# RA register map
Vendor: Renesas; Series: All Chips; File version: x.xx
Registers are 32-bit, read-write, reset 0x0 unless marked. A register's access mark holds for its fields unless they carry their own. Offsets are from the block's base; [hi:lo] are bit positions; {n}, {i} and the like mark numbered series; 'fields as' and 'values as' point back to an identical list.

## R_SDADC0
Base 0x4009C000
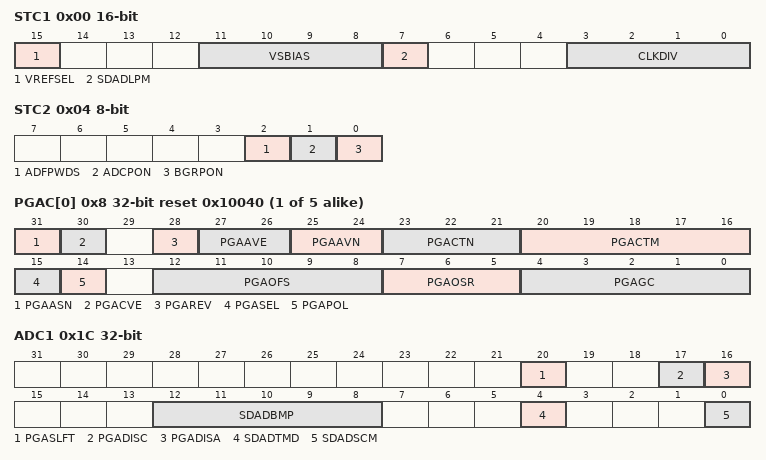
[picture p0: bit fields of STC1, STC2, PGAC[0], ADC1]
0x00 STC1 16-bit reset not defined — Startup Control Register 1
  [15] VREFSEL — VREF mode select
    0=Internal VREF Mode
  [11:8] VSBIAS — Reference voltage select
    0=0.8V; 1=1.0V; 2=1.2V; 3=1.4V; 4=1.6V; 5=1.8V; 6=2.0V; 7=2.2V; 15=2.4V(only available when VREFSEL=0)
  [7] SDADLPM — A/D conversion operation model select
    0=Normal A/D conversion mode, SDADC Reference Clock: 4 MHz, Oversampingly clock: 1MHz
  [3:0] CLKDIV — SDADC24 Reference Clock Division
    0=No Division; {v}=SDADCCLK/{v+1} (v=1..5); 6=SDADCCLK/8; 7=SDADCCLK/12; 8=SDADCCLK/16
0x04 STC2 8-bit — Startup Control Register 2
  [2] ADFPWDS — ADC reference supply part
    0=Power of ADREG controlled by BGRPON register; 1=Power of ADREG is off regardless of BGRPON setting
  [1] ADCPON — ADREG forced power-down
    0=Turn off power to VBIAS, PGA and sigma-delta A/D converter; 1=Turn on power to VBIAS, PGA and sigma-delta A/D converter
  [0] BGRPON — BGR part power control
    0=Turn off power to ADBGR, SBIAS, VREFI, and ADREG; 1=Turn onpower to ADBGR, SBIAS, VREFI, and ADREG
{0x8+4i} PGAC[{i}] (i=0..4) reset 0x10040 — Input Multiplexer {i} Setting Register
  [31] PGAASN — Selection of the mode for specifying the number of A/D conversions in ADSCAN
    0=Specify 1 to 8,032 times by using the value set in the PGACTN[2:0] and PGACTM[4:0] bits; 1=Specify 1 to 255 times linearly by using the value set in the PGACTN[2:0] and PGACTM[4:0] bits
  [30] PGACVE — Calibration enable
    0=Do not calculate the calibration correction factor; 1=Calculate the calibration correction factor
  [28] PGAREV — Single-End Input A/D Converted Data Inversion Select
    0=Do not invert the conversion result data; 1=Invert the conversion result data
  [27:26] PGAAVE — Selection of averaging processing
    0=Do not average the A/D conversion results; 1=Do not average the A/D conversion results; 2=Average the A/D conversion results and generates SDADC_ADI each time an A/D conversion occurs; 3=Perform averaging, and generate SDADC_ADI at each time of average value output (A/D conversion is performed N times)
  [25:24] PGAAVN — Selection of the number of data to be averaged
    0=8; 1=16; 2=32; 3=64
  [23:21] PGACTN — Coefficient (n) selection of the A/D conversion count (N) in AUTOSCAN
    {v}={v} (v=0..7)
  [20:16] PGACTM — Coefficient (m) selection of the A/D conversion count (N) in AUTOSCAN
  [15] PGASEL — Analog Channel Input Mode Select
    0=Differential input mode; 1=Single-end input mode
  [14] PGAPOL — Polarity select
    0=Positive-side single-end input; 1=Negative-side single-end input
  [12:8] PGAOFS — Offset voltage select
  [7:5] PGAOSR — Oversampling ratio select
    0=64; 1=128; 2=256; 3=512; 4=1024; 5=2048; other=others (Settings are prohibited.)
  [4:0] PGAGC — Gain selection of a programmable gain instrumentation amplifier ( Gset1, Gset2, Gtotal )
    0=(1, 1, 1); 4=(2, 1, 2); 8=(3, 1, 3); 12=(4, 1, 4); 16=(8, 1, 8); 1=(1, 2, 2); 5=(2, 2, 4); 9=(3, 2, 6); 13=(4, 2, 8); 17=(8, 2, 16); 2=(1, 4, 4); 6=(2, 4, 8); 10=(3, 4, 12); 14=(4, 4, 16); 18=(8, 4, 32); 3=(1, 8, 8); 7=(2, 8, 16); 11=(3, 8, 24); 15=(4, 8, 32); other=others (Settings are prohibited.)
0x1C ADC1 — Sigma-Delta A/D Converter Control Register 1
  [20] PGASLFT — PGA offset self-diagnosis enable
    0=Disable PGA offset self-diagnosis; 1=Enable PGA offset self-diagnosis
  [17] PGADISC — Disconnection Detection Assist Setting
    0=Discharge; 1=Pre-charge
  [16] PGADISA — Control of disconnection detection
    0=Normal operation; 1=State of disconnection detection
  [12:8] SDADBMP — A/D conversion control of the signal from input multiplexer
  [4] SDADTMD — Selection of A/D conversion trigger signal
    0=Software trigger (conversion is started by a write to SFR); 1=Hardware trigger (conversion is started in synchronization with the event signal selected by ELC_SDADC24)
  [0] SDADSCM — Selection of autoscan mode
    0=Continuous scan mode; 1=Single scan mode
0x20 ADC2 8-bit — Sigma-Delta A/D Converter Control Register 2
  [0] SDADST — Control of A/D conversion
    0=Stop A/D conversion; 1=Start A/D conversion
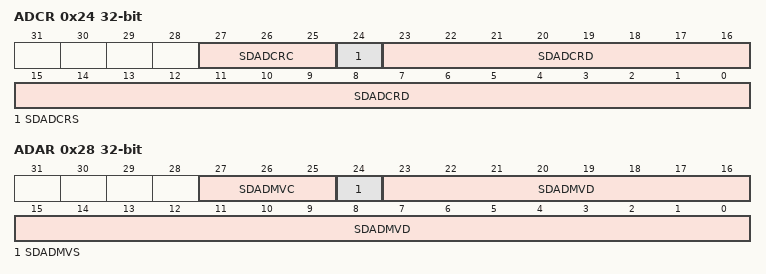
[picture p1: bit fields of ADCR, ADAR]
0x24 ADCR — Sigma-delta A/D Converter Conversion Result Register
  [27:25] SDADCRC ro — Channel number for an A/D conversion result
    0=Reset value (Conversion result is invalid); {v}=Input multiplexer {v-1} (ANSD{v-1}P / ANSD{v-1}N) (v=1..4); 5=Input multiplexer 4 (AMP0O / AMP1O)
  [24] SDADCRS ro — Status of an A/D conversion result
    0=Normal status (within the range); 1=Overflow occurred
  [23:0] SDADCRD ro — The 24-bit A/D conversion result
0x28 ADAR ro — Sigma-delta A/D Converter Average Value Register
  [27:25] SDADMVC — Channel number for an A/D conversion result
    values as ADCR.SDADCRC
  [24] SDADMVS — Status of an A/D conversion result
    0=Normal status (within the range); 1=Overflow occurred
  [23:0] SDADMVD — The 24-bit A/D average value
0x30 CLBC 8-bit — Calibration Control Register
  [1:0] CLBMD — These bits are read as 0. The write value should be 0.
    0=Internal calibration mode; 1=External offset calibration mode; 2=External gain calibration mode; 3=Settings are prohibited
0x34 CLBSTR 8-bit — Calibration Start Control Register
  [0] CLBST — Calibration start control
    0=Disable writing; 1=Start calibration
0x3C CLBSSR 8-bit ro — Calibration Status Register
  [0] CLBSS — Calibration status
    0=Calibration is not running; 1=Calibration is running
